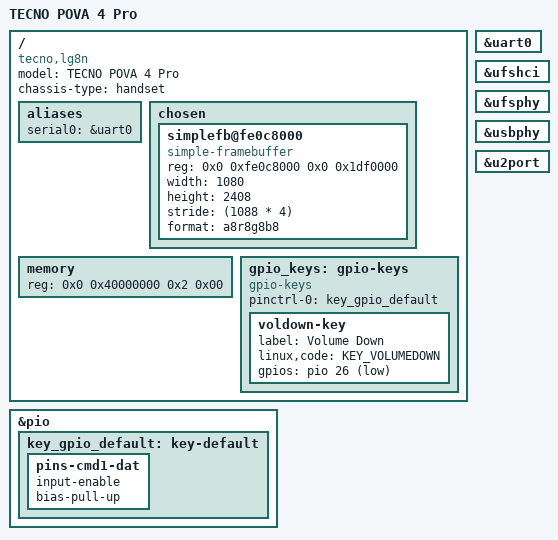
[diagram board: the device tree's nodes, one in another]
/*
 * SPDX-License-Identifier: (GPL-2.0 OR MIT)
 */

/dts-v1/;
#include "mt6789.dtsi"
#include <dt-bindings/gpio/gpio.h>
#include <dt-bindings/input/input.h>

/ {
	model = "TECNO POVA 4 Pro";
	chassis-type = "handset";
	compatible = "tecno,lg8n", "mediatek,mt6789";

	#address-cells = <2>;
	#size-cells = <2>;

	aliases {
		serial0 = &uart0;
	};

	chosen {
		#address-cells = <2>;
		#size-cells = <2>;
		ranges;

		simplefb@fe0c8000 {
			compatible = "simple-framebuffer";
			reg = <0x0 0xfe0c8000 0x0 0x1df0000>;
			width = <1080>;
			height = <2408>;
			stride = <(1088 * 4)>;
			format = "a8r8g8b8";
		};
	};

	memory {
		device_type = "memory";
		reg = <0x0 0x40000000 0x2 0x00>;
	};

	gpio_keys: gpio-keys {
		compatible = "gpio-keys";

		pinctrl-0 = <&key_gpio_default>;
		pinctrl-names = "default";

		voldown-key {
			label = "Volume Down";
			linux,code = <KEY_VOLUMEDOWN>;
			gpios = <&pio 26 GPIO_ACTIVE_LOW>;
		};
	};
};

&pio {
	key_gpio_default: key-default {
		pins-cmd1-dat {
			input-enable;
			bias-pull-up;
		};
	};
};

&uart0 {
	status = "okay";
};

&ufshci {
	status = "okay";
};

&ufsphy {
	status = "okay";
};

&usbphy {
	status = "okay";
};

&u2port {
	status = "okay";
};
